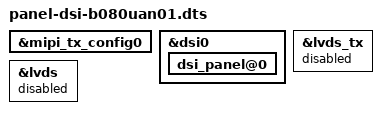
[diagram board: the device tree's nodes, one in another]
/dts-v1/;
/plugin/;

/ {
	fragment@0 {
		target = <&mipi_tx_config0>;
		__overlay__ {
			status = "okay";
		};
	};

	fragment@1 {
		target = <&dsi0>;
		__overlay__ {
			status = "okay";
			dsi_panel@0 {
				status = "okay";
			};
		};
	};

	fragment@2 {
		target = <&lvds_tx>;
		__overlay__ {
			status = "disabled";
		};
	};
	
	fragment@3 {
		target = <&lvds>;
		__overlay__ {
			status = "disabled";
		};
	};
};
